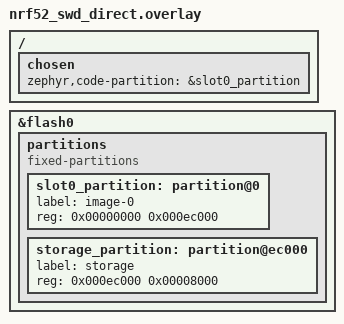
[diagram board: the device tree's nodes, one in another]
/ {
	chosen {
		zephyr,code-partition = &slot0_partition;
	};
};

&flash0 {
	/delete-node/ partitions;
	partitions {
		compatible = "fixed-partitions";
		#address-cells = <1>;
		#size-cells = <1>;

		slot0_partition: partition@0 {
			label = "image-0";
			reg = <0x00000000 0x000ec000>;
		};

		storage_partition: partition@ec000 {
			label = "storage";
			reg = <0x000ec000 0x00008000>;
		};
	};
};
